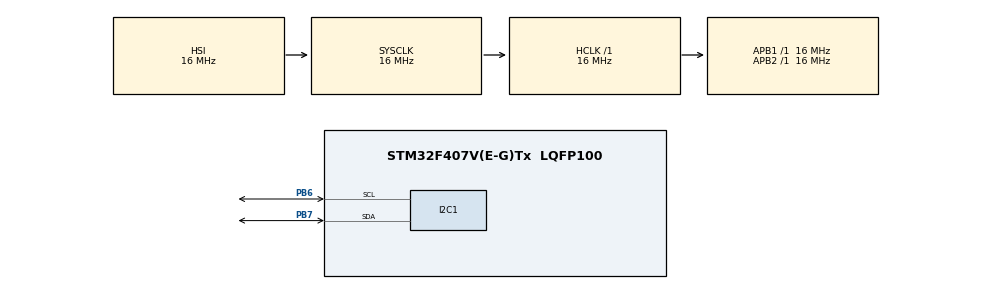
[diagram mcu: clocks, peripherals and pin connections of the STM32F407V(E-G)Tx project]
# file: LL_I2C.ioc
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I2C1.AddressingMode=I2C_ADDRESSINGMODE_7BIT
I2C1.DutyCycle=I2C_DUTYCYCLE_16_9
I2C1.GeneralCallMode=I2C_GENERALCALL_DISABLE
I2C1.I2C_Mode=I2C_Fast
I2C1.NoStretchMode=I2C_NOSTRETCH_ENABLE
I2C1.OwnAddress=0x3A
Mcu.Family=STM32F4
Mcu.Name=STM32F407V(E-G)Tx
Mcu.Package=LQFP100
NVIC.PriorityGroup=NVIC_PRIORITYGROUP_4
PB6.Mode=I2C
PB6.Signal=I2C1_SCL
PB7.Mode=I2C
PB7.Signal=I2C1_SDA
ProjectManager.HeapSize=0x200
ProjectManager.StackSize=0x400
ProjectManager.TargetToolchain=STM32CubeIDE
RCC.AHBFreq_Value=16000000
RCC.APB1Freq_Value=16000000
RCC.APB2Freq_Value=16000000
RCC.CortexFreq_Value=16000000
RCC.HSE_VALUE=25000000
RCC.HSI_VALUE=16000000
RCC.LSE_VALUE=32768
RCC.SYSCLKFreq_VALUE=16000000
RCC.VCOOutputFreq_Value=192000000
board=custom

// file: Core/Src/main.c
/* USER CODE BEGIN Header */
/**
  ******************************************************************************
  * @file           : main.c
  * @brief          : Main program body
  ******************************************************************************
  * @attention
  *
  * Copyright (c) 2023 STMicroelectronics.
  * All rights reserved.
  *
  * This software is licensed under terms that can be found in the LICENSE file
  * in the root directory of this software component.
  * If no LICENSE file comes with this software, it is provided AS-IS.
  *
  ******************************************************************************
  */
/* USER CODE END Header */
#include "main.h"
#include "i2c.h"
#include "gpio.h"

/* USER CODE BEGIN Includes */
#include <stdlib.h>
#include "driver_mpu6050_basic.h"
/* USER CODE END Includes */

void SystemClock_Config(void);

/* USER CODE BEGIN 0 */
/**
 * @brief
 * @retval 0: operacion correcta
 * @retval 1: error
 */
uint8_t i2c_reg_write(I2C_TypeDef *I2C, uint8_t SlaveADDR, uint8_t regAddr, uint8_t *pData, uint16_t len, uint32_t timeout){
	uint32_t temp= 0;
	uint32_t ticks = HAL_GetTick();

	if(len <= 0 || pData == NULL){
		return 1;
	}
	//esperar que el bus este desocupado
	do{
		if((HAL_GetTick() - ticks)> timeout){
			return 1;
		}
	}while(LL_I2C_IsActiveFlag_BUSY(I2C)  == 1);

	//generar la condicion de inicio (star)
	I2C->CR1 |= I2C_CR1_START;
	do{
		if((HAL_GetTick() - ticks)> timeout){
			I2C->CR1 |= I2C_CR1_STOP;
			return 1;
		}
	}while(LL_I2C_IsActiveFlag_SB(I2C)  == 0);

	//enviar la direccion del esclavo
	SlaveADDR = SlaveADDR <<1;					//[A6:A0] [R/W] (W = 0, R = 1)
	SlaveADDR &= ~1;
	LL_I2C_TransmitData8(I2C, SlaveADDR);
	//I2C->DR = SlaveADDR;

	do{
		if((HAL_GetTick() - ticks)> timeout){
			I2C->CR1 |= I2C_CR1_STOP;
			return 1;
		}
	}while(LL_I2C_IsActiveFlag_ADDR(I2C)  == 0);
	//while((I2C->SR1 & I2C_SR1_ADDR) == 0);

	//Limpiar los registros de estado
	temp = I2C->SR1;
	temp = I2C->SR2;
	(void)temp;

	//enviar la direccion de la region
	do{
		if((HAL_GetTick() - ticks)>timeout){
			I2C->CR1 |= I2C_CR1_STOP;
			return 1;
		}
	}while(!(I2C->SR1 & I2C_SR1_TXE));
	LL_I2C_TransmitData8(I2C, regAddr);

	//enviar los n datos

	while(len>0){
		if(LL_I2C_IsActiveFlag_TXE(I2C)){
			LL_I2C_TransmitData8(I2C, *pData);
			pData++;
			len--;
			if(len == 0){
				break;
			}
		}
		if((HAL_GetTick() - ticks)>timeout){
			I2C->CR1 |= I2C_CR1_STOP;
			return 1;
		}
	}
	//wait
	do{
		if((HAL_GetTick() - ticks)>timeout){
			I2C->CR1 |= I2C_CR1_STOP;
			return 1;
		}
	}while((LL_I2C_IsActiveFlag_TXE(I2C) == 0) && (LL_I2C_IsActiveFlag_BTF(I2C) == 0));

	//stop condition
	I2C->CR1 |= I2C_CR1_STOP;
	return 0;

}

uint8_t i2c_reg_read(I2C_TypeDef *I2C, uint8_t SlaveADDR, uint8_t regAddr, uint8_t *pData, uint16_t len, uint32_t timeout){
	uint32_t temp= 0;
	uint32_t ticks = HAL_GetTick();

	if(len <= 0 || pData == NULL){
		return 1;
	}
	//esperar que el bus este desocupado
	do{
		if((HAL_GetTick() - ticks)> timeout){
			return 1;
		}
	}while(LL_I2C_IsActiveFlag_BUSY(I2C)  == 1);

	//generar la condicion de inicio (star)
	I2C->CR1 |= I2C_CR1_START;
	do{
		if((HAL_GetTick() - ticks)> timeout){
			I2C->CR1 |= I2C_CR1_STOP;
			return 1;
		}
	}while(LL_I2C_IsActiveFlag_SB(I2C)  == 0);

	//enviar la direccion del esclavo
	SlaveADDR = SlaveADDR <<1;					//[A6:A0] [R/W] (W = 0, R = 1)
	SlaveADDR &= ~1;
	LL_I2C_TransmitData8(I2C, SlaveADDR);
	//I2C->DR = SlaveADDR;

	do{
		if((HAL_GetTick() - ticks)> timeout){
			I2C->CR1 |= I2C_CR1_STOP;
			return 1;
		}
	}while(LL_I2C_IsActiveFlag_ADDR(I2C)  == 0);
	//while((I2C->SR1 & I2C_SR1_ADDR) == 0);

	//Limpiar los registros de estado
	temp = I2C->SR1;
	temp = I2C->SR2;
	(void)temp;

	//enviar la direccion base a leerse
	//enviar la direccion de la region
	do{
		if((HAL_GetTick() - ticks)>timeout){
			I2C->CR1 |= I2C_CR1_STOP;
			return 1;
		}
	}while(!(I2C->SR1 & I2C_SR1_TXE));
	LL_I2C_TransmitData8(I2C, regAddr);

	//una nueva condicion de inicio
	//wait
	do{
		if((HAL_GetTick() - ticks)>timeout){
			I2C->CR1 |= I2C_CR1_STOP;
			return 1;
		}
	}while((LL_I2C_IsActiveFlag_TXE(I2C) == 0) && (LL_I2C_IsActiveFlag_BTF(I2C) == 0));

	//generar la condicion de inicio (star)
	I2C->CR1 |= I2C_CR1_START;
	do{
		if((HAL_GetTick() - ticks)> timeout){
			I2C->CR1 |= I2C_CR1_STOP;
			return 1;
		}
	}while(LL_I2C_IsActiveFlag_SB(I2C)  == 0);
	//enviar la direccion del esclavo

	SlaveADDR |= 1;
	LL_I2C_TransmitData8(I2C, SlaveADDR);
	do{
		if((HAL_GetTick() - ticks)> timeout){
			I2C->CR1 |= I2C_CR1_STOP;
			return 1;
		}
	}while(LL_I2C_IsActiveFlag_ADDR(I2C)  == 0);

	//Limpiar los registros de estado
	temp = I2C->SR1;
	temp = I2C->SR2;
	(void)temp;

	//leer bytes
	I2C->CR1  |= I2C_CR1_ACK;

	while(len> 0){
		if(len == 1){
			I2C->CR1 &=~ I2C_CR1_ACK;

			do{
				if((HAL_GetTick() - ticks)>timeout){
					I2C1->CR1 |= I2C_CR1_STOP;
					return 1;
				}
			}while(LL_I2C_IsActiveFlag_RXNE(I2C) == 0);

			I2C1->CR1 |= I2C_CR1_STOP;

			//LEER
			*pData = LL_I2C_ReceiveData8(I2C);
			len--;
			break;
		}else{
			//wait
			do{
				if((HAL_GetTick() - ticks)>timeout){
					I2C1->CR1 |= I2C_CR1_STOP;
					return 1;
				}
			}while(LL_I2C_IsActiveFlag_RXNE(I2C) == 0);
			*pData = I2C->DR;
			pData++;
			len--;
		}
	}

	return 0;
}
/* USER CODE END 0 */

int main(void)
{

  /* MCU Configuration--------------------------------------------------------*/

  /* Reset of all peripherals, Initializes the Flash interface and the Systick. */
  HAL_Init();

  /* Configure the system clock */
  SystemClock_Config();

  /* Initialize all configured peripherals */
  MX_GPIO_Init();
  MX_I2C1_Init();
  /* USER CODE BEGIN 2 */

  mpu6050_basic_init(0x68);

  float a[3];
  float g[3];
  float temp;
  /* USER CODE END 2 */

  /* Infinite loop */
  while (1)
  {

    /* USER CODE BEGIN 3 */
	  mpu6050_basic_read(a, g);
	  mpu6050_basic_read_temperature(&temp);
	  HAL_Delay(500);
  }
  /* USER CODE END 3 */
}

void SystemClock_Config(void)
{
  RCC_OscInitTypeDef RCC_OscInitStruct = {0};
  RCC_ClkInitTypeDef RCC_ClkInitStruct = {0};

  /** Configure the main internal regulator output voltage
  */
  __HAL_RCC_PWR_CLK_ENABLE();
  __HAL_PWR_VOLTAGESCALING_CONFIG(PWR_REGULATOR_VOLTAGE_SCALE1);

  /** Initializes the RCC Oscillators according to the specified parameters
  * in the RCC_OscInitTypeDef structure.
  */
  RCC_OscInitStruct.OscillatorType = RCC_OSCILLATORTYPE_HSI;
  RCC_OscInitStruct.HSIState = RCC_HSI_ON;
  RCC_OscInitStruct.HSICalibrationValue = RCC_HSICALIBRATION_DEFAULT;
  RCC_OscInitStruct.PLL.PLLState = RCC_PLL_NONE;
  if (HAL_RCC_OscConfig(&RCC_OscInitStruct) != HAL_OK)
  {
    Error_Handler();
  }

  /** Initializes the CPU, AHB and APB buses clocks
  */
  RCC_ClkInitStruct.ClockType = RCC_CLOCKTYPE_HCLK|RCC_CLOCKTYPE_SYSCLK
                              |RCC_CLOCKTYPE_PCLK1|RCC_CLOCKTYPE_PCLK2;
  RCC_ClkInitStruct.SYSCLKSource = RCC_SYSCLKSOURCE_HSI;
  RCC_ClkInitStruct.AHBCLKDivider = RCC_SYSCLK_DIV1;
  RCC_ClkInitStruct.APB1CLKDivider = RCC_HCLK_DIV1;
  RCC_ClkInitStruct.APB2CLKDivider = RCC_HCLK_DIV1;

  if (HAL_RCC_ClockConfig(&RCC_ClkInitStruct, FLASH_LATENCY_0) != HAL_OK)
  {
    Error_Handler();
  }
}

void Error_Handler(void)
{
  __disable_irq();
  while (1)
  {
  }
}
